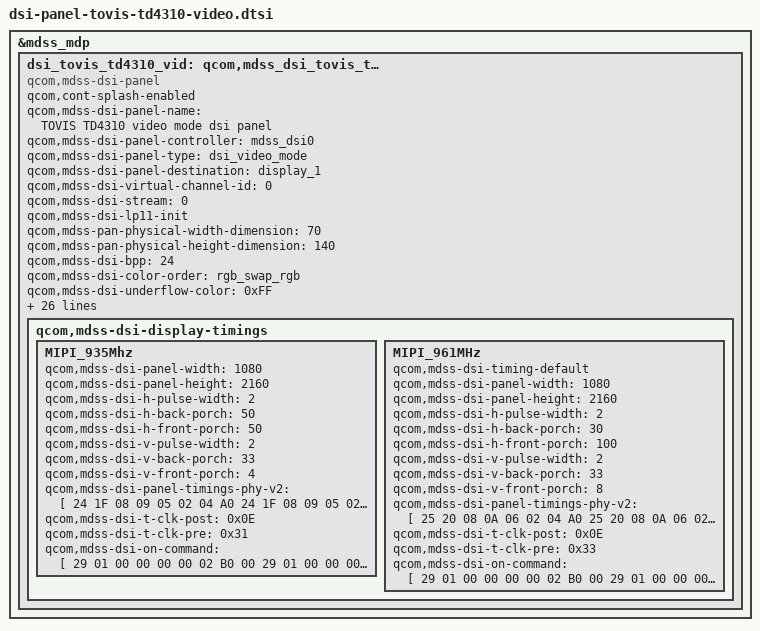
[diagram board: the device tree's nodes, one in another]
/* Copyright (c) 2014, Code Aurora Forum. All rights reserved.
 *
 * This program is free software; you can redistribute it and/or modify
 * it under the terms of the GNU General Public License version 2 and
 * only version 2 as published by the Free Software Foundation.
 *
 * This program is distributed in the hope that it will be useful,
 * but WITHOUT ANY WARRANTY; without even the implied warranty of
 * MERCHANTABILITY or FITNESS FOR A PARTICULAR PURPOSE.  See the
 * GNU General Public License for more details.
 */

&mdss_mdp {
	dsi_tovis_td4310_vid: qcom,mdss_dsi_tovis_td4310_video {
		compatible = "qcom,mdss-dsi-panel";
		status = "ok";
		qcom,cont-splash-enabled;
		qcom,mdss-dsi-panel-name = "TOVIS TD4310 video mode dsi panel";
		qcom,mdss-dsi-panel-controller = <&mdss_dsi0>;
		qcom,mdss-dsi-panel-type = "dsi_video_mode";
		qcom,mdss-dsi-panel-destination = "display_1";
		qcom,mdss-dsi-virtual-channel-id = <0>;
		qcom,mdss-dsi-stream = <0>;
		qcom,mdss-dsi-lp11-init;

		qcom,mdss-pan-physical-width-dimension = <70>;
		qcom,mdss-pan-physical-height-dimension = <140>;

		qcom,mdss-dsi-bpp = <24>;
		qcom,mdss-dsi-color-order = "rgb_swap_rgb";
		qcom,mdss-dsi-underflow-color = <0xFF>;
		qcom,mdss-dsi-border-color = <0xFF>;

		qcom,mdss-dsi-off-command = [
			// Display off
			05 01 00 00 78 00 01
			28
			// Display off APO code
			29 01 00 00 00 00 02
			B0 00
			29 01 00 00 00 00 31
			C1 04 40 00 FF FF FF FF FF EA FF FF FF FF FF FF
			FF FF FF FF 7F F5 FF FF FF FF 0F 00 00 00 00 00
			00 00 00 40 02 22 02 06 0A 00 00 01 00 01 00 00
			00
			29 01 00 00 00 00 1C
			CB FF FF FF FF 0F FC 76 E0 F6 03 11 F0 00 0D 00
			00 00 00 00 00 00 00 00 00 00 00 00
			// Sleep in
			05 01 00 00 78 00 01
			10
		];

		qcom,mdss-dsi-on-command-state = "dsi_lp_mode";
		qcom,mdss-dsi-off-command-state = "dsi_hs_mode";
		qcom,mdss-dsi-h-sync-pulse = <0>;
		qcom,mdss-dsi-traffic-mode = "non_burst_sync_event";
		qcom,mdss-dsi-lane-map = "lane_map_0123";
		qcom,mdss-dsi-dma-trigger = "trigger_sw";
		qcom,mdss-dsi-mdp-trigger = "none";
		qcom,mdss-dsi-bllp-eof-power-mode;
		qcom,mdss-dsi-bllp-power-mode;
		//qcom,ulps-enabled;
		//qcom,suspend-ulps-enabled;
		qcom,mdss-dsi-lane-0-state;
		qcom,mdss-dsi-lane-1-state;
		qcom,mdss-dsi-lane-2-state;
		qcom,mdss-dsi-lane-3-state;
		qcom,mdss-dsi-tx-eot-append;

		qcom,mdss-dsi-bl-min-level = <1>;
		qcom,mdss-dsi-bl-max-level = <255>;
		qcom,mdss-dsi-reset-sequence = <0 1>, <1 1>;

		lge,blmap-size = <256>;
		lge,blmap = <
			0	1	1	1	1	1	1	1	1	1	/* 0 ~ 9 */
			1	1	1	1	1	1	1	1	2	2	/* 10 ~ 19 */
			2	2	2	3	3	3	4	4	5	5	/* 20 ~ 29 */
			6	6	7	7	8	9	9	10	11	12	/* 30 ~ 39 */
			12	13	14	15	16	17	18	20	21	22	/* 40 ~ 49 */
			23	24	26	27	29	30	32	33	35	36	/* 50 ~ 59 */
			40	40	41	43	45	47	49	51	53	55	/* 60 ~ 69 */
			57	59	61	64	66	68	71	73	76	78	/* 70 ~ 79 */
			81	83	86	89	92	94	97	100	103	106	/* 80 ~ 89 */
			109	112	116	119	122	125	129	132	136	139	/* 90 ~ 99 */
			143	146	150	154	158	161	165	169	180	180	/* 100 ~ 109 */
			181	185	190	194	198	203	207	211	216	221	/* 110 ~ 119 */
			225	230	235	239	244	249	254	259	264	269	/* 120 ~ 129 */
			275	280	285	290	296	301	307	312	318	324	/* 130 ~ 139 */
			329	335	341	347	353	359	365	371	378	384	/* 140 ~ 149 */
			390	397	403	409	416	423	429	436	440	450	/* 150 ~ 159 */
			457	464	471	478	485	492	499	507	514	522	/* 160 ~ 169 */
			529	537	544	552	560	568	575	583	591	599	/* 170 ~ 179 */
			608	616	624	632	641	649	658	666	675	684	/* 180 ~ 189 */
			692	701	710	719	728	737	746	755	765	774	/* 190 ~ 199 */
			783	793	802	812	821	831	839	839	861	871	/* 200 ~ 209 */
			881	891	901	911	921	932	942	953	963	974	/* 210 ~ 219 */
			984	995	1006	1017	1028	1039	1050	1061	1072	1083	/* 220 ~ 229 */
			1095	1106	1118	1129	1141	1152	1164	1176	1188	1200	/* 230 ~ 239 */
			1212	1224	1236	1248	1261	1273	1285	1298	1310	1323	/* 240 ~ 249 */
			1336	1348	1361	1374	1387	1400					/* 250 ~ 255 */
		>;
		lge,panel-type = "TOVIS-TD4310";
		lge,ddic = "synaptics,td4310";

		qcom,mdss-dsi-display-timings {
			MIPI_935Mhz {
				qcom,mdss-dsi-panel-width = <1080>;
				qcom,mdss-dsi-panel-height = <2160>;
				qcom,mdss-dsi-h-pulse-width = <2>;
				qcom,mdss-dsi-h-back-porch = <50>;
				qcom,mdss-dsi-h-front-porch = <50>;
				qcom,mdss-dsi-v-pulse-width = <2>;
				qcom,mdss-dsi-v-back-porch = <33>;
				qcom,mdss-dsi-v-front-porch = <4>;
				qcom,mdss-dsi-panel-timings-phy-v2 = [
					24 1F 08 09 05 02 04 A0
					24 1F 08 09 05 02 04 A0
					24 1F 08 09 05 02 04 A0
					24 1F 08 09 05 02 04 A0
					24 1C 08 09 05 02 04 A0
				];
				qcom,mdss-dsi-t-clk-post = <0x0E>;
				qcom,mdss-dsi-t-clk-pre = <0x31>;
				qcom,mdss-dsi-on-command = [
					// MCAP: Manufacturer Command Access Protect
					29 01 00 00 00 00 02
					B0 00
					// Interface Setting
					29 01 00 00 00 00 04
					B3 31 00 06
					// Interface ID Setting
					29 01 00 00 00 00 02
					B4 00
					// DSI Control +
					29 01 00 00 00 00 06
					B6 33 5B 81 12 00
					// Backlight Control 1 (C = 1 GUI)
					29 01 00 00 00 00 08
					B8 57 3D 19 1E 0A 50 50
					// Backlight Control 2 (C = 2 still)
					29 01 00 00 00 00 08
					B9 6F 3D 28 3C 14 C8 C8
					// Backlight Control 3 (C = 3 movie)
					29 01 00 00 00 00 08
					BA B5 33 41 64 23 A0 A0
					// Sunlight Readability Enhancement (SRE control 1, SRE = 1 weak setting)
					29 01 00 00 00 00 03
					BB 14 14
					// Sunlight Readability Enhancement (SRE control 2, SRE = 2 middle setting)
					29 01 00 00 00 00 03
					BC 37 32
					// Sunlight Readability Enhancement (SRE control 3, SRE = 3 strong setting)
					29 01 00 00 00 00 03
					BD 64 02
					// External Clock Setting
					29 01 00 00 00 00 02
					BE 04
					// Skew Rate Adjustment
					29 01 00 00 00 00 02
					C0 00
					// Display Setting1 Common
					29 01 00 00 00 00 31
					C1 04 40 00 FF FF FF FF FF FF FF FF FF FF FF FF
					FF FF FF FF FF FF FF FF FF FF 0F 00 00 00 00 00
					00 00 00 40 02 22 02 06 0A 00 00 01 00 01 00 00
					00
					// Display Setting2
					29 01 00 00 00 00 19
					C2 01 F8 70 0A 6A 0A 0C 10 00 08 30 00 00 00 00
					00 00 00 00 0E 00 00 00 00
					// Display Setting3
					29 01 00 00 00 00 3F
					C3 86 D8 6D 86 D0 00 00 00 00 00 40 B4 0B 00 00
					45 14 51 00 00 01 01 03 28 00 01 00 01 00 00 13
					00 13 00 2C 01 00 00 00 00 00 00 00 00 00 00 00
					00 24 00 24 00 5A 02 00 00 00 00 00 00 40 00
					// Source Timing Setting and SOUT Equalize Setting
					29 01 00 00 00 00 15
					C4 70 00 00 00 00 00 00 00 00 02 02 31 01 00 00
					00 02 01 01 01
					// Crosshair
					29 01 00 00 00 00 09
					C5 08 00 00 00 00 70 00 00
					// LTPS Timing Setting
					29 01 00 00 00 00 40
					C6 45 01 44 02 3D 01 0E 01 02 01 02 01 02 00 00
					00 00 04 10 04 45 00 47 53 00 00 00 00 00 00 00
					00 00 00 00 00 00 00 00 00 00 00 00 00 00 00 00
					00 00 00 00 00 00 00 00 00 00 00 00 00 00 00 00
					// Gamma Setting Common Set
					29 01 00 00 00 00 27
					C7 00 1A 28 38 46 50 65 73 7E 88 39 43 50 64 6F
					7C 8E 99 A2 00 1A 28 38 46 50 65 73 7E 88 39 43
					50 64 6F 7C 8E 99 A2
					// Digital Gamma Setting 1
					29 01 00 00 00 00 38
					C8 00 00 00 00 00 FC 00 00 00 00 00 FC 00 00 00
					00 00 FC 00 00 00 00 00 FC 00 00 00 00 00 FC 00
					00 00 00 00 FC 00 00 00 00 00 FC 00 00 00 00 00
					FC 00 00 00 00 00 FC 00
					// Digital Gamma Setting 2
					29 01 00 00 00 00 14
					C9 00 00 00 00 00 FC 00 00 00 00 00 FC 00 00 00
					00 00 FC 00
					// Color Enhancement
					29 01 00 00 00 00 2C
					CA 1C FC FC FC 00 00 00 00 00 00 00 00 00 00 00
					00 00 00 00 00 00 00 00 00 00 00 00 00 00 00 00
					00 00 00 00 00 00 00 00 00 00 00 00
					// Panel PIN Control
					29 01 00 00 00 00 1C
					CB FF FF FF FF 0F 80 00 00 10 00 11 F0 00 0D 00
					00 00 00 00 00 00 00 00 00 00 00 00
					// Panel Interface Control
					29 01 00 00 00 00 03
					CC 22 00
					// Touch Control
					29 01 00 00 00 00 27
					CD 1F 00 21 00 21 00 5C 02 C1 C1 DE DE B1 B1 DD
					DD 01 00 00 00 00 00 00 00 00 00 00 00 00 00 00
					00 00 00 00 00 00 A2
					// Backlight Control 4
					29 01 00 00 00 00 1A
					CE 5D 40 49 53 59 5E 63 68 6E 74 7E 8A 98 A8 BB
					D0 FF 04 00 04 04 42 00 69 5A
					// Panel Synchronous Output
					29 01 00 00 00 00 03
					CF 48 1D
					// Power Setting for CHGP
					29 01 00 00 00 00 14
					D0 33 54 D4 31 01 10 10 10 19 19 00 00 00 00 00
					00 00 6D 65
					// Touch Period and Source Drive Mode Select
					29 01 00 00 00 00 02
					D1 00
					// Power Setting for Internal Power
					29 01 00 00 00 00 16
					D3 1B 3B BB 77 77 77 BB B3 33 00 00 6C 69 C7 C7
					33 BB F2 FD C6 0B
					// VCOM Setting
					29 01 00 00 00 00 0B
					D5 00 00 00 02 40 02 40 01 00 00
					// Timing Control for Power on Sequencer Test Mode
					29 01 00 00 00 00 22
					D7 86 FF 03 05 41 24 80 1F C7 1F 1B 00 0C 07 20
					00 00 00 00 00 0C F0 1F 00 0C 00 00 AA 67 7E 1D
					06 00
					// Power Sequencer Control
					29 01 00 00 00 00 08
					D9 00 02 14 3D 00 77 02
					// Outline Sharpening Control
					29 01 00 00 00 00 05
					DD 30 06 23 65
					// Test Image Generator
					29 01 00 00 00 00 05
					DE 00 3F FF 90
					// ESD Detect Setting
					29 01 00 00 00 00 02
					EA 9F
					// Glass Break Detect Setting
					29 01 00 00 00 00 04
					EE 41 51 00
					// Test Register
					29 01 00 00 00 00 04
					F1 00 00 00
					// Sequencer Test Control
					29 01 00 00 00 00 02
					D6 41
					// write_display_brightness
					39 01 00 00 00 00 02
					51 FF
					// write_control_display
					39 01 00 00 00 00 02
					53 0C
					// write_content_adaptive_brightness_control
					39 01 00 00 00 00 02
					55 00
					// Sleep out
					05 01 00 00 78 00 01
					11
					// Display on APO noraml
					29 01 00 00 00 00 02
					B0 00
					29 01 00 00 00 00 31
					C1 04 40 00 FF 5F 6B 89 B0 6A 85 0F A3 FC FF FF
					FF 65 84 1F 2C 65 CB B0 F6 FE 0F 00 00 00 00 00
					00 00 00 40 02 22 02 06 0A 00 00 01 00 05 00 00
					00
					29 01 00 00 00 00 1C
					CB FF FF FF FF 0F 00 00 00 00 00 11 F0 00 0D 00
					00 00 00 00 00 00 00 00 00 00 00 00
					// Display on
					05 01 00 00 78 00 01
					29
				];
			};
			MIPI_961MHz {
				qcom,mdss-dsi-timing-default;
				qcom,mdss-dsi-panel-width = <1080>;
				qcom,mdss-dsi-panel-height = <2160>;
				qcom,mdss-dsi-h-pulse-width = <2>;
				qcom,mdss-dsi-h-back-porch = <30>;
				qcom,mdss-dsi-h-front-porch = <100>;
				qcom,mdss-dsi-v-pulse-width = <2>;
				qcom,mdss-dsi-v-back-porch = <33>;
				qcom,mdss-dsi-v-front-porch = <8>;
				qcom,mdss-dsi-panel-timings-phy-v2 = [
					25 20 08 0A 06 02 04 A0
					25 20 08 0A 06 02 04 A0
					25 20 08 0A 06 02 04 A0
					25 20 08 0A 06 02 04 A0
					25 1D 08 0A 06 02 04 A0
				];
				qcom,mdss-dsi-t-clk-post = <0x0E>;
				qcom,mdss-dsi-t-clk-pre = <0x33>;
				qcom,mdss-dsi-on-command = [
					// MCAP: Manufacturer Command Access Protect
					29 01 00 00 00 00 02
					B0 00
					// Interface Setting
					29 01 00 00 00 00 04
					B3 31 00 06
					// Interface ID Setting
					29 01 00 00 00 00 02
					B4 00
					// DSI Control +
					29 01 00 00 00 00 06
					B6 33 5B 81 12 00
					// Backlight Control 1 (C = 1 GUI)
					29 01 00 00 00 00 08
					B8 57 3D 19 1E 0A 50 50
					// Backlight Control 2 (C = 2 still)
					29 01 00 00 00 00 08
					B9 6F 3D 28 3C 14 C8 C8
					// Backlight Control 3 (C = 3 movie)
					29 01 00 00 00 00 08
					BA B5 33 41 64 23 A0 A0
					// Sunlight Readability Enhancement (SRE control 1, SRE = 1 weak setting)
					29 01 00 00 00 00 03
					BB 14 14
					// Sunlight Readability Enhancement (SRE control 2, SRE = 2 middle setting)
					29 01 00 00 00 00 03
					BC 37 32
					// Sunlight Readability Enhancement (SRE control 3, SRE = 3 strong setting)
					29 01 00 00 00 00 03
					BD 64 02
					// External Clock Setting
					29 01 00 00 00 00 02
					BE 04
					// Skew Rate Adjustment
					29 01 00 00 00 00 02
					C0 00
					// Display Setting1 Common
					29 01 00 00 00 00 31
					C1 04 40 00 FF FF FF FF FF FF FF FF FF FF FF FF
					FF FF FF FF FF FF FF FF FF FF 0F 00 00 00 00 00
					00 00 00 40 02 22 02 06 0A 00 00 01 00 01 00 00
					00
					// Display Setting2
					29 01 00 00 00 00 19
					C2 01 F8 70 0A 6A 0A 0C 10 00 08 30 00 00 00 00
					00 00 00 00 0E 00 00 00 00
					// Display Setting3
					29 01 00 00 00 00 3F
					C3 86 D8 6D 86 D0 00 00 00 00 00 40 B4 0B 00 00
					45 14 51 00 00 01 01 03 28 00 01 00 01 00 00 13
					00 13 00 2C 01 00 00 00 00 00 00 00 00 00 00 00
					00 24 00 24 00 5A 02 00 00 00 00 00 00 40 00
					// Source Timing Setting and SOUT Equalize Setting
					29 01 00 00 00 00 15
					C4 70 00 00 00 00 00 00 00 00 02 02 31 01 00 00
					00 02 01 01 01
					// Crosshair
					29 01 00 00 00 00 09
					C5 08 00 00 00 00 70 00 00
					// LTPS Timing Setting
					29 01 00 00 00 00 40
					C6 45 01 44 02 3D 01 0E 01 02 01 02 01 02 00 00
					00 00 04 10 04 45 00 47 53 00 00 00 00 00 00 00
					00 00 00 00 00 00 00 00 00 00 00 00 00 00 00 00
					00 00 00 00 00 00 00 00 00 00 00 00 00 00 00 00
					// Gamma Setting Common Set
					29 01 00 00 00 00 27
					C7 00 1A 28 38 46 50 65 73 7E 88 39 43 50 64 6F
					7C 8E 99 A2 00 1A 28 38 46 50 65 73 7E 88 39 43
					50 64 6F 7C 8E 99 A2
					// Digital Gamma Setting 1
					29 01 00 00 00 00 38
					C8 00 00 00 00 00 FC 00 00 00 00 00 FC 00 00 00
					00 00 FC 00 00 00 00 00 FC 00 00 00 00 00 FC 00
					00 00 00 00 FC 00 00 00 00 00 FC 00 00 00 00 00
					FC 00 00 00 00 00 FC 00
					// Digital Gamma Setting 2
					29 01 00 00 00 00 14
					C9 00 00 00 00 00 FC 00 00 00 00 00 FC 00 00 00
					00 00 FC 00
					// Color Enhancement
					29 01 00 00 00 00 2C
					CA 1C FC FC FC 00 00 00 00 00 00 00 00 00 00 00
					00 00 00 00 00 00 00 00 00 00 00 00 00 00 00 00
					00 00 00 00 00 00 00 00 00 00 00 00
					// Panel PIN Control
					29 01 00 00 00 00 1C
					CB FF FF FF FF 0F 80 00 00 10 00 11 F0 00 0D 00
					00 00 00 00 00 00 00 00 00 00 00 00
					// Panel Interface Control
					29 01 00 00 00 00 03
					CC 22 00
					// Touch Control
					29 01 00 00 00 00 27
					CD 1F 00 21 00 21 00 5C 02 C1 C1 DE DE B1 B1 DD
					DD 01 00 00 00 00 00 00 00 00 00 00 00 00 00 00
					00 00 00 00 00 00 A2
					// Backlight Control 4
					29 01 00 00 00 00 1A
					CE 5D 40 49 53 59 5E 63 68 6E 74 7E 8A 98 A8 BB
					D0 FF 04 00 04 04 42 00 69 5A
					// Panel Synchronous Output
					29 01 00 00 00 00 03
					CF 48 1D
					// Power Setting for CHGP
					29 01 00 00 00 00 14
					D0 33 54 D4 31 01 10 10 10 19 19 00 00 00 00 00
					00 00 6D 65
					// Touch Period and Source Drive Mode Select
					29 01 00 00 00 00 02
					D1 00
					// Power Setting for Internal Power
					29 01 00 00 00 00 16
					D3 1B 3B BB 77 77 77 BB B3 33 00 00 6C 69 C7 C7
					33 BB F2 FD C6 0B
					// VCOM Setting
					29 01 00 00 00 00 0B
					D5 00 00 00 02 40 02 40 01 00 00
					// Timing Control for Power on Sequencer Test Mode
					29 01 00 00 00 00 22
					D7 86 FF 03 05 41 24 80 1F C7 1F 1B 00 0C 07 20
					00 00 00 00 00 0C F0 1F 00 0C 00 00 AA 67 7E 1D
					06 00
					// Power Sequencer Control
					29 01 00 00 00 00 08
					D9 00 02 14 3D 00 77 02
					// Outline Sharpening Control
					29 01 00 00 00 00 05
					DD 30 06 23 65
					// Test Image Generator
					29 01 00 00 00 00 05
					DE 00 3F FF 90
					// ESD Detect Setting
					29 01 00 00 00 00 02
					EA 9F
					// Glass Break Detect Setting
					29 01 00 00 00 00 04
					EE 41 51 00
					// Test Register
					29 01 00 00 00 00 04
					F1 00 00 00
					// Sequencer Test Control
					29 01 00 00 00 00 02
					D6 41
					// write_display_brightness
					39 01 00 00 00 00 02
					51 FF
					// write_control_display
					39 01 00 00 00 00 02
					53 0C
					// write_content_adaptive_brightness_control
					39 01 00 00 00 00 02
					55 00
					// Sleep out
					05 01 00 00 78 00 01
					11
					// Display on APO noraml
					29 01 00 00 00 00 02
					B0 00
					29 01 00 00 00 00 31
					C1 04 40 00 FF 5F 6B 89 B0 6A 85 0F A3 FC FF FF
					FF 65 84 1F 2C 65 CB B0 F6 FE 0F 00 00 00 00 00
					00 00 00 40 02 22 02 06 0A 00 00 01 00 05 00 00
					00
					29 01 00 00 00 00 1C
					CB FF FF FF FF 0F 00 00 00 00 00 11 F0 00 0D 00
					00 00 00 00 00 00 00 00 00 00 00 00
					// Display on
					05 01 00 00 78 00 01
					29
				];
			};
		};
	};
};
